AUTOSAR XML (schema 00049)
package /Application/DltConfig
  dlt log channel to process mapping DltLogChannelToProcessMapping_ServiceCreator_TO_ServiceCreator: dlt-log-channel=ServiceCreator, process=ServiceCreator
package /Application/Executable
  executable ServiceCreator: category=APPLICATION_LEVEL, logging-behavior=USES-LOGGING, reporting-behavior=REPORTS-EXECUTION-STATE, version=1.0.0
    root sw component prototype AA: application-type=ServiceCreator
package /Application/Manifest
  37 x service instance to port prototype mapping:
    ServiceCreator_AA_PPort_BCM_WiperWash: port-prototype=AA.PPort_BCM_WiperWash, service-instance=EEVP_ServiceCreator_Provider_BCM_WiperWash
    ServiceCreator_AA_PPort_BmsInfoSrv: port-prototype=AA.PPort_BmsInfoSrv, service-instance=EEVP_ServiceCreator_Provider_BmsInfoSrv
    ServiceCreator_AA_PPort_Ctrl_MoodLamp: port-prototype=AA.PPort_Ctrl_MoodLamp, service-instance=EEVP_ServiceCreator_Provider_Ctrl_MoodLamp
    ServiceCreator_AA_PPort_Ctrl_RearCurtain: port-prototype=AA.PPort_Ctrl_RearCurtain, service-instance=EEVP_ServiceCreator_Provider_Ctrl_RearCurtain
    ServiceCreator_AA_PPort_DMS_Func: port-prototype=AA.PPort_DMS_Func, service-instance=EEVP_ServiceCreator_Provider_DMS_Func
    ServiceCreator_AA_PPort_MsgInfoSrv: port-prototype=AA.PPort_MsgInfoSrv, service-instance=EEVP_ServiceCreator_Provider_MsgInfoSrv
    ServiceCreator_AA_PPort_ServiceManagement: port-prototype=AA.PPort_ServiceManagement, service-instance=EEVP_ServiceCreator_Provider_ServiceManagement
    ServiceCreator_AA_PPort_SmartFilmCont: port-prototype=AA.PPort_SmartFilmCont, service-instance=EEVP_ServiceCreator_Provider_SmartFilmCont
    ServiceCreator_AA_PPort_Snsr_FaceDetectModule: port-prototype=AA.PPort_Snsr_FaceDetectModule, service-instance=EEVP_ServiceCreator_Provider_Snsr_FaceDetectModule
    ServiceCreator_AA_PPort_Snsr_HeartBeat: port-prototype=AA.PPort_Snsr_HeartBeat, service-instance=EEVP_ServiceCreator_Provider_Snsr_Heartbeat
    ServiceCreator_AA_PPort_Snsr_USS: port-prototype=AA.PPort_Snsr_USS, service-instance=EEVP_ServiceCreator_Provider_Snsr_USS
    ServiceCreator_AA_PPort_TMS_AC: port-prototype=AA.PPort_TMS_AC, service-instance=EEVP_ServiceCreator_Provider_TMS_AC
    ServiceCreator_AA_PPort_TMS_EnvMonitor: port-prototype=AA.PPort_TMS_EnvMonitor, service-instance=EEVP_ServiceCreator_Provider_TMS_EnvMonitor
    ServiceCreator_AA_PPort_TMS_Fragrance: port-prototype=AA.PPort_TMS_Fragrance, service-instance=EEVP_ServiceCreator_Provider_TMS_Fragrance
    ServiceCreator_AA_PPort_TMS_Purifier: port-prototype=AA.PPort_TMS_Purifier, service-instance=EEVP_ServiceCreator_Provider_TMS_Purifier
    ServiceCreator_AA_PPort_TMS_Ventilation: port-prototype=AA.PPort_TMS_Ventilation, service-instance=EEVP_ServiceCreator_Provider_TMS_Ventilation
    ServiceCreator_AA_PPort_VCS_AccrPedal: port-prototype=AA.PPort_VCS_AccrPedal, service-instance=EEVP_ServiceCreator_Provider_VCS_AccrPedal
    ServiceCreator_AA_PPort_VCS_Brake: port-prototype=AA.PPort_VCS_Brake, service-instance=EEVP_ServiceCreator_Provider_VCS_Brake
    ServiceCreator_AA_PPort_VCS_BrakePedal: port-prototype=AA.PPort_VCS_BrakePedal, service-instance=EEVP_ServiceCreator_Provider_VCS_BrakePedal
    ServiceCreator_AA_PPort_VCS_EPB: port-prototype=AA.PPort_VCS_EPB, service-instance=EEVP_ServiceCreator_Provider_VCS_EPB
    ServiceCreator_AA_PPort_VCS_Gear: port-prototype=AA.PPort_VCS_Gear, service-instance=EEVP_ServiceCreator_Provider_VCS_Gear
    ServiceCreator_AA_PPort_VCS_VehSpd: port-prototype=AA.PPort_VCS_VehSpd, service-instance=EEVP_ServiceCreator_Provider_VCS_VehSpd
    ServiceCreator_AA_RPort_BCM_Horn: port-prototype=AA.RPort_BCM_Horn, service-instance=EEVP_ServiceCreator_Consumer_BCM_Horn
    ServiceCreator_AA_RPort_BCM_WiperWash: port-prototype=AA.RPort_BCM_WiperWash, service-instance=EEVP_ServiceCreator_Consumer_BCM_WiperWash
    ServiceCreator_AA_RPort_Ctrl_MoodLamp: port-prototype=AA.RPort_Ctrl_MoodLamp, service-instance=EEVP_ServiceCreator_Consumer_Ctrl_MoodLamp
    ServiceCreator_AA_RPort_Ctrl_RearCurtain: port-prototype=AA.RPort_Ctrl_RearCurtain, service-instance=EEVP_ServiceCreator_Consumer_Ctrl_RearCurtain
    ServiceCreator_AA_RPort_EevpControlSoaMlm: port-prototype=AA.RPort_EevpControlSoaMlm, service-instance=EEVP_ServiceCreator_Consumer_EevpControlSoaMlm
    ServiceCreator_AA_RPort_SmartFilmCont: port-prototype=AA.RPort_SmartFilmCont, service-instance=EEVP_ServiceCreator_Consumer_SmartFilmCont
    ServiceCreator_AA_RPort_Snsr_FaceDetectModule: port-prototype=AA.RPort_Snsr_FaceDetectModule, service-instance=EEVP_ServiceCreator_Consumer_Snsr_FaceDetectModule
    ServiceCreator_AA_RPort_TMS_AC: port-prototype=AA.RPort_TMS_AC, service-instance=EEVP_ServiceCreator_Consumer_TMS_AC
    ServiceCreator_AA_RPort_TMS_EnvMonitor: port-prototype=AA.RPort_TMS_EnvMonitor, service-instance=EEVP_ServiceCreator_Consumer_BCM_WiperWash
    ServiceCreator_AA_RPort_TMS_Fragrance: port-prototype=AA.RPort_TMS_Fragrance, service-instance=EEVP_ServiceCreator_Consumer_TMS_Fragrance
    ServiceCreator_AA_RPort_TMS_Purifier: port-prototype=AA.RPort_TMS_Purifier, service-instance=EEVP_ServiceCreator_Consumer_TMS_Purifier
    ServiceCreator_AA_RPort_TMS_Ventilation: port-prototype=AA.RPort_TMS_Ventilation, service-instance=EEVP_ServiceCreator_Consumer_TMS_Ventilation
    ServiceCreator_AA_RPort_VCS_Brake: port-prototype=AA.RPort_VCS_Brake, service-instance=EEVP_ServiceCreator_Consumer_VCS_Brake
    ServiceCreator_AA_RPort_VCS_Gear: port-prototype=AA.RPort_VCS_Gear, service-instance=EEVP_ServiceCreator_Consumer_VCS_Gear
    ServiceCreator_AA_RPort_VCS_TqDmd: port-prototype=AA.RPort_VCS_TqDmd, service-instance=EEVP_ServiceCreator_Consumer_VCS_TqDmd
package /Application/Process
  process ServiceCreator: executable=ServiceCreator, state-dependent-startup-config{execution-dependency=CM.Running, function-group-state=MachineFG.Startup, resource-group=DefaultResourceGroup, startup-config=ServiceCreator}
    process state machine ServiceCreator: type=ProcessState
package /Application/StartupConfig
  startup config set EEVP_ServiceCreator_StartupConfig
    startup config ServiceCreator: scheduling-policy=SCHED_OTHER, scheduling-priority=0
package /Application/SwComponent
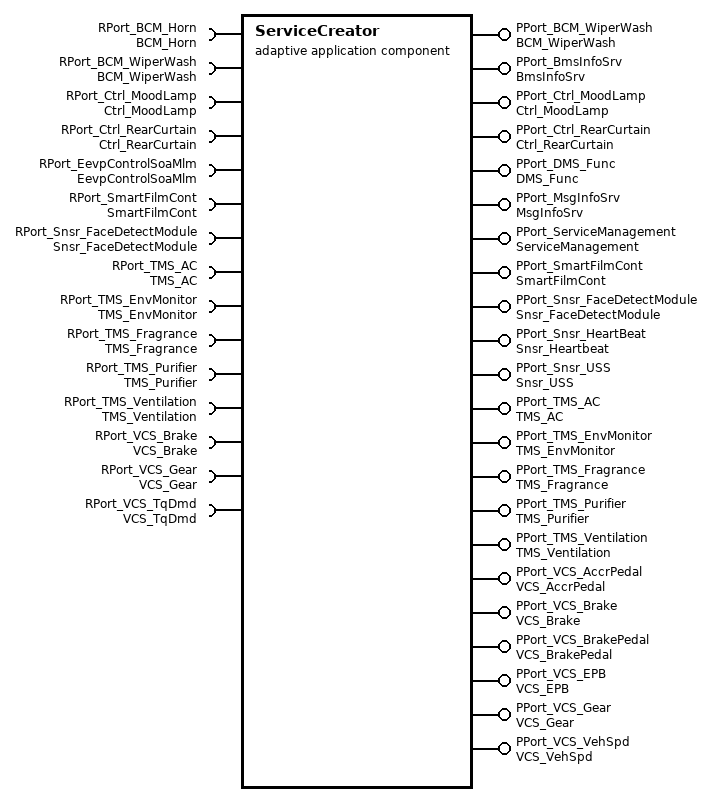
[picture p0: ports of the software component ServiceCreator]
  adaptive application sw component type ServiceCreator
    22 x provide port:
      PPort_BCM_WiperWash: provided-interface=BCM_WiperWash
      PPort_BmsInfoSrv: provided-interface=BmsInfoSrv
      PPort_Ctrl_MoodLamp: provided-interface=Ctrl_MoodLamp
      PPort_Ctrl_RearCurtain: provided-interface=Ctrl_RearCurtain
      PPort_DMS_Func: provided-interface=DMS_Func
      PPort_MsgInfoSrv: provided-interface=MsgInfoSrv
      PPort_ServiceManagement: provided-interface=ServiceManagement
      PPort_SmartFilmCont: provided-interface=SmartFilmCont
      PPort_Snsr_FaceDetectModule: provided-interface=Snsr_FaceDetectModule
      PPort_Snsr_HeartBeat: provided-interface=Snsr_Heartbeat
      PPort_Snsr_USS: provided-interface=Snsr_USS
      PPort_TMS_AC: provided-interface=TMS_AC
      PPort_TMS_EnvMonitor: provided-interface=TMS_EnvMonitor
      PPort_TMS_Fragrance: provided-interface=TMS_Fragrance
      PPort_TMS_Purifier: provided-interface=TMS_Purifier
      PPort_TMS_Ventilation: provided-interface=TMS_Ventilation
      PPort_VCS_AccrPedal: provided-interface=VCS_AccrPedal
      PPort_VCS_Brake: provided-interface=VCS_Brake
      PPort_VCS_BrakePedal: provided-interface=VCS_BrakePedal
      PPort_VCS_EPB: provided-interface=VCS_EPB
      PPort_VCS_Gear: provided-interface=VCS_Gear
      PPort_VCS_VehSpd: provided-interface=VCS_VehSpd
    15 x require port:
      RPort_BCM_Horn: required-interface=BCM_Horn
      RPort_BCM_WiperWash: required-interface=BCM_WiperWash
      RPort_Ctrl_MoodLamp: required-interface=Ctrl_MoodLamp
      RPort_Ctrl_RearCurtain: required-interface=Ctrl_RearCurtain
      RPort_EevpControlSoaMlm: required-interface=EevpControlSoaMlm
      RPort_SmartFilmCont: required-interface=SmartFilmCont
      RPort_Snsr_FaceDetectModule: required-interface=Snsr_FaceDetectModule
      RPort_TMS_AC: required-interface=TMS_AC
      RPort_TMS_EnvMonitor: required-interface=TMS_EnvMonitor
      RPort_TMS_Fragrance: required-interface=TMS_Fragrance
      RPort_TMS_Purifier: required-interface=TMS_Purifier
      RPort_TMS_Ventilation: required-interface=TMS_Ventilation
      RPort_VCS_Brake: required-interface=VCS_Brake
      RPort_VCS_Gear: required-interface=VCS_Gear
      RPort_VCS_TqDmd: required-interface=VCS_TqDmd
